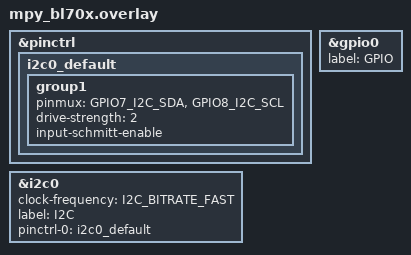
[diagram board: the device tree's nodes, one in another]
&pinctrl {
	i2c0_default: i2c0_default {
		group1 {
			pinmux = <GPIO7_I2C_SDA>, <GPIO8_I2C_SCL>;
			drive-strength = <2>;
			input-schmitt-enable;
		};
	};
};


&gpio0 {
	status = "okay";
	label = "GPIO";
};

&i2c0 {
	status = "okay";
	clock-frequency = <I2C_BITRATE_FAST>;
	label = "I2C";
	pinctrl-0 = <&i2c0_default>;
	pinctrl-names = "default";
};
